AUTOSAR XML (schema 4-2-2)
package /RootP_ASWC_A7G
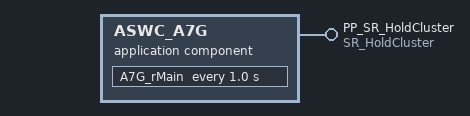
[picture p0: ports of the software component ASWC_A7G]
  application sw component type ASWC_A7G
    provide port PP_SR_HoldCluster: nonqueued-sender-com-spec{data-element=HoldCluster, uses-end-to-end-protection=0, init-value=0}, provided-interface=SR_HoldCluster
    behavior IB_ASWC_A7G: handle-termination-and-restart=NO-SUPPORT
      timing event TmgEvt_A7G_rMain: start-on-event=A7G_rMain, period=1.0
      runnable A7G_rMain
        data-send-points:
          access dsp_HoldCluster: accessed-variable=PP_SR_HoldCluster.HoldCluster
package /RootP_Implementation
  swc implementation Implementation_A7G: programming-language=C, sw-version=1.0.0, vendor-id=0, behavior=IB_ASWC_A7G
    code-descriptors:
      code SRC: artifact-descriptors=autosar-engineering-object={short-label=EngObject, category=SWSRC}
    resource consumption Resources
